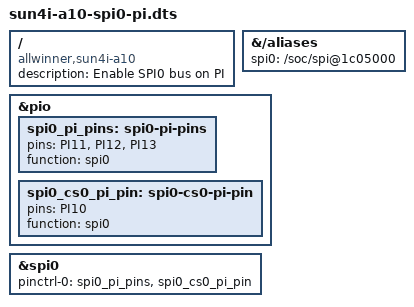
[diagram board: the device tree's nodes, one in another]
/dts-v1/;
/plugin/;

/ {
	compatible = "allwinner,sun4i-a10";
	description = "Enable SPI0 bus on PI";

	fragment@0 {
		target-path = "/aliases";
		__overlay__ {
			spi0 = "/soc/spi@1c05000";
		};
	};

	fragment@1 {
		target = <&pio>;
		__overlay__ {
			spi0_pi_pins: spi0-pi-pins {
				pins = "PI11", "PI12", "PI13";
				function = "spi0";
			};

			spi0_cs0_pi_pin: spi0-cs0-pi-pin {
				pins = "PI10";
				function = "spi0";
			};
		};
	};

	fragment@2 {
		target = <&spi0>;
		__overlay__ {
			pinctrl-names = "default";
			pinctrl-0 = <&spi0_pi_pins>, <&spi0_cs0_pi_pin>;
			status = "okay";
		};
	};
};
